# RL7005_IP_SVD register map
Vendor: Realtek
Registers are 32-bit, read-write, reset 0x0 unless marked. A register's access mark holds for its fields unless they carry their own. Offsets are from the block's base; [hi:lo] are bit positions; lines under a group give offsets from that group; {n}, {i} and the like mark numbered series.

## PAGE17
Base 0x40000000
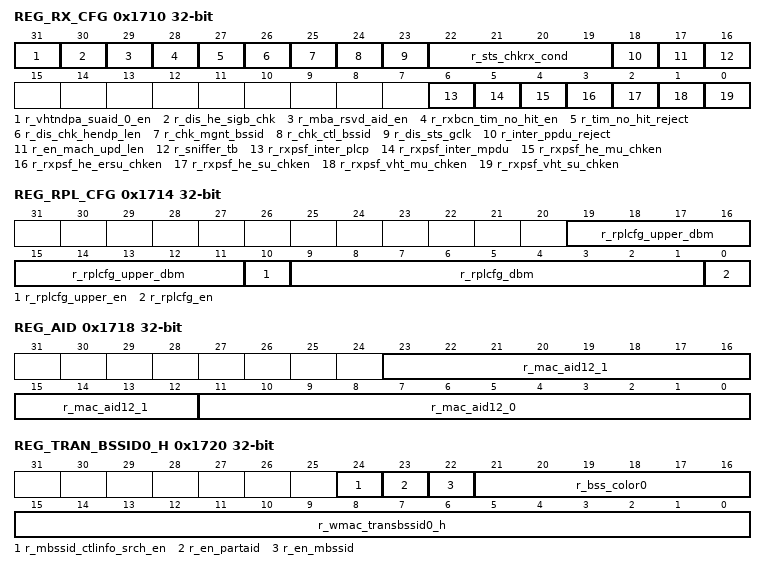
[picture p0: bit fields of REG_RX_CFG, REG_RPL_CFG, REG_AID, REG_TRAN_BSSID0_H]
0x1710 REG_RX_CFG — rx configure register
  [31] r_vhtndpa_suaid_0_en — when set, will receive vht/he su ndpa which aid field is set to 0.
  [30] r_dis_he_sigb_chk — when set, disable check he-mu sigb crc8
  [29] r_mba_rsvd_aid_en — enable parsing resevd aid msta-ba for pre-association
  [28] r_rxbcn_tim_no_hit_en — enable rxbcn_ok_int when receiving bcn with tim_no_hit,set 0: rxbcn_ok_int will only assert when tim_hit
  [27] r_tim_no_hit_reject — enable reject tim no hit beacon
  [26] r_dis_chk_hendp_len — disable check HE NDP lsig length value
  [25] r_chk_mgnt_bssid — enable check management frame bssid
  [24] r_chk_ctl_bssid — enable check trigger,vht/hendpa and block ack bssid
  [23] r_dis_sts_gclk — disable ppdu status clock gating
  [22:19] r_sts_chkrx_cond — check macrx condition when receiving ppdu status
  [18] r_inter_ppdu_reject — enable reject inter ppdu
  [17] r_en_mach_upd_len — enable macrx_pktfifo_ctl update mpdu length in MACHDR_CHK state
  [16] r_sniffer_tb — enable to receive TB PPDU for debug mode
  [6] r_rxpsf_inter_plcp — enable invalid packet check for inter ppdu, inter ppdu valid when plcp is inter bss
  [5] r_rxpsf_inter_mpdu — enable invalid packet check for inter ppdu, inter ppdu valid when plcp and mac header are inter bss
  [4] r_rxpsf_he_mu_chken — enable HE MU invalid packet check for mac header
  [3] r_rxpsf_he_ersu_chken — enable HE ER SU invalid packet check for mac header
  [2] r_rxpsf_he_su_chken — enable HE SU invalid packet check for mac header
  [1] r_rxpsf_vht_mu_chken — enable VHT MU invalid packet check for mac header
  [0] r_rxpsf_vht_su_chken — enable VHT SU invalid packet check for mac header
0x1714 REG_RPL_CFG — rx receive power level configure register
  [19:11] r_rplcfg_upper_dbm — rx power upper level
  [10] r_rplcfg_upper_en — enable use r_rplcfg_upper_dbm as rx power level
  [9:1] r_rplcfg_dbm — rx power level
  [0] r_rplcfg_en — enable use r_rplcfg_dbm as rx power level
0x1718 REG_AID — aid register
  [23:12] r_mac_aid12_1 — aid1
  [11:0] r_mac_aid12_0 — aid0
0x171C REG_TRAN_BSSID0_L — trasmitted bssid register0_l
  [31:0] r_wmac_transbssid0_l — lower 32 bits of transmitted bssid0
0x1720 REG_TRAN_BSSID0_H — trasmitted bssid register0_h
  [24] r_mbssid_ctlinfo_srch_en — when set, rx trigger and vht/he ndpa, will search control info using assocaiated bssid
  [23] r_en_partaid — enable inter ppdu decision according to partial aid for VHT ppdu
  [22] r_en_mbssid — enable multibssid function
  [21:16] r_bss_color0 — bss color of current BSS
  [15:0] r_wmac_transbssid0_h — higher 16 bits of transmitted bssid0
0x1724 REG_TRAN_BSSID1_L — trasmitted bssid register1_l
  [31:0] r_wmac_transbssid1_l — lower 32 bits of transmitted bssid1
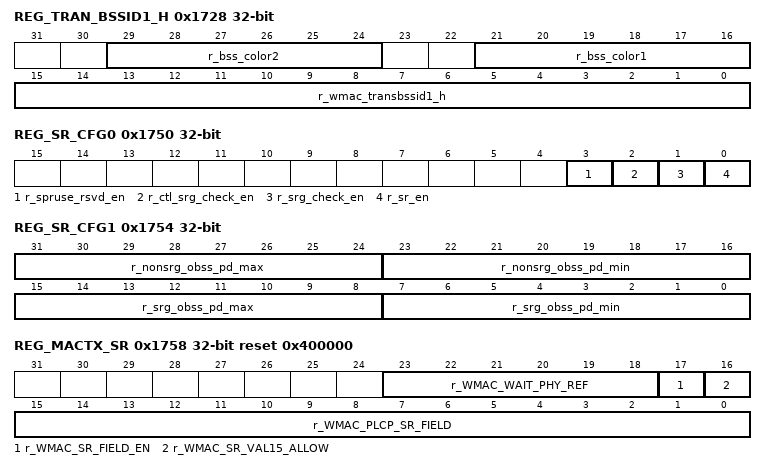
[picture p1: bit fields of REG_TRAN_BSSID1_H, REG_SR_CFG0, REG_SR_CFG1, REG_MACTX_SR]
0x1728 REG_TRAN_BSSID1_H — trasmitted bssid register1_h
  [29:24] r_bss_color2 — bss color of port2
  [21:16] r_bss_color1 — bss color of current BSS
  [15:0] r_wmac_transbssid1_h — higher 16 bits of transmitted bssid1
0x172C REG_GID_POS_EN_l — VHT group id position enable register
  [31:0] r_gid_position_en_l — VHT group id position enable
{0x1730+4i} REG_GID_POS{i} (i=0..3) — VHT group id position{i} register
  [31:0] r_gid_position{i} — VHT group id position{i}
0x1740 REG_BSSCOLOR_BITMAP_L — bss color bitmap register_l
  [31:0] r_bsscolor_bitmap_l — low 32bits bss color bitmap
0x1744 REG_BSSCOLOR_BITMAP_H — bss color bitmap register_h
  [31:0] r_bsscolor_bitmap_h — high 32bits bss color bitmap
0x1748 REG_PBSSID_BITMAP_L — partial bssid bitmap register_l
  [31:0] r_partial_bssid_bitmap_l — low 32bits partial bssid bitmap
0x174C REG_PBSSID_BITMAP_H — partial bssid bitmap register_h
  [31:0] r_partial_bssid_bitmap_h — high 32bits partial bssid bitmap
0x1750 REG_SR_CFG0 — spatial reuse configure register0
  [3] r_spruse_rsvd_en — enable spatial reuse when plcp header spatial reuse field value smaller than 14 or value is 15 and is srg ppdu
  [2] r_ctl_srg_check_en — enable control packet srg ppdu check
  [1] r_srg_check_en — enable srg ppdu check
  [0] r_sr_en — enable spatial reuse function
0x1754 REG_SR_CFG1 — spatial reuse configure register1
  [31:24] r_nonsrg_obss_pd_max — the maximum value of non_SRG OBSS_PD
  [23:16] r_nonsrg_obss_pd_min — the minimum value of non_SRG OBSS_PD
  [15:8] r_srg_obss_pd_max — the maximum value of OBSS_PD
  [7:0] r_srg_obss_pd_min — the minimum value of OBSS_PD
0x1758 REG_MACTX_SR reset 0x400000 — SR field configure
  [23:18] r_WMAC_WAIT_PHY_REF — mactx hang handle, reset mactx if the phy_txen is set and wait the begin pulse of phy_txon timeout
  [17] r_WMAC_SR_FIELD_EN — enable sr field reg cfg
  [16] r_WMAC_SR_VAL15_ALLOW — sr field can be the value 15
  [15:0] r_WMAC_PLCP_SR_FIELD — value of SR field
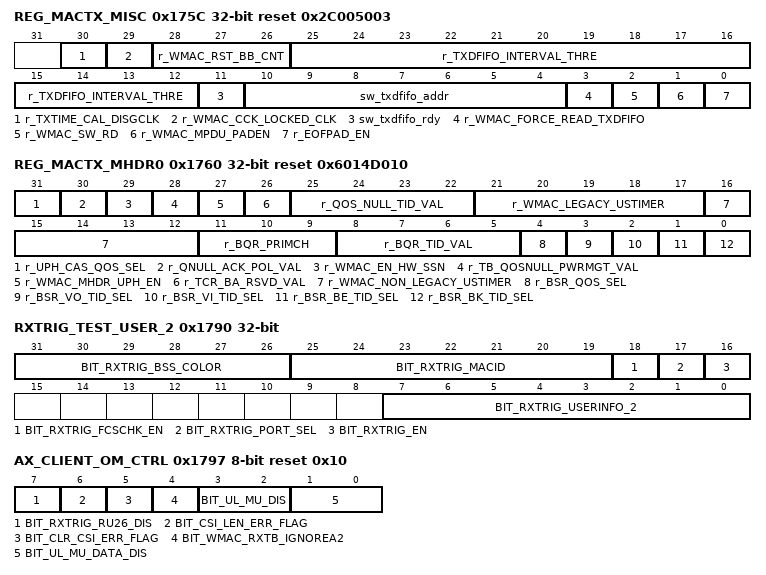
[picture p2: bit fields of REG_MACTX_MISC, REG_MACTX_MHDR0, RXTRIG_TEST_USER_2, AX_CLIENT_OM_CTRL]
0x175C REG_MACTX_MISC reset 0x2C005003 — misc ctrl cfg
  [30] r_TXTIME_CAL_DISGCLK — disable the clk gating for txtime compute module
  [29] r_WMAC_CCK_LOCKED_CLK — indicate that the transmit frequency and symbol clocks are derived from the same oscillator
  [28:26] r_WMAC_RST_BB_CNT — macclk cycle number of wmac_rst_bb signal
  [25:12] r_TXDFIFO_INTERVAL_THRE — the interval threshold between txdfifo write and read pointer, if the interval is smaller than the threshold, mactx_mpdu moudle can pad dummy between mpdu(if eanbled)
  [11] sw_txdfifo_rdy — sw read txd fifo ready
  [10:4] sw_txdfifo_addr — sw read txd fifo address,[6:1] is address, [0] : 0 read low 32bit; 1 read high 32bit;
  [3] r_WMAC_FORCE_READ_TXDFIFO — during tx procedure, force read txd fifo, which is only use at the situation when bb is hang.
  [2] r_WMAC_SW_RD — eanble sw read txdfifo
  [1] r_WMAC_MPDU_PADEN — when txdfifo underflow ,eanble the mactx_mpdu moudle to pad dummy between mpdu.
  [0] r_EOFPAD_EN — enable eof pad operation at the end of mpdu
0x1760 REG_MACTX_MHDR0 reset 0x6014D010 — MAC header configure
  [31] r_UPH_CAS_QOS_SEL — UPH and CAS HTC control field enable
  [30] r_QNULL_ACK_POL_VAL — basic trigger resp tb QOS NULL ack policy bit 0 value
  [29] r_WMAC_EN_HW_SSN — enable the hw ssn for qos null frame.
  [28] r_TB_QOSNULL_PWRMGT_VAL — the power management bit value in tb qos null, used during twt operation
  [27] r_WMAC_MHDR_UPH_EN — eanble reg wirte HTC field of tb_ppdu, which contain UPH a-control(4)
  [26] r_TCR_BA_RSVD_VAL — multi-sta BA bactl rsvd filed value
  [25:22] r_QOS_NULL_TID_VAL — tid value of qos null
  [21:17] r_WMAC_LEGACY_USTIMER — timer cnt before bb fetch txd for ofdm
  [16:12] r_WMAC_NON_LEGACY_USTIMER — timer cnt before bb fetch txd for he/vht/ht/cck
  [11:9] r_BQR_PRIMCH — shift bqr bitmap to the allocatied primary 20M channel
  [8:5] r_BQR_TID_VAL — bandwidth query report TID value
  [4] r_BSR_QOS_SEL — Buffer status report enable
  [3] r_BSR_VO_TID_SEL — 1: tid 7; 0: tid 6;
  [2] r_BSR_VI_TID_SEL — 1: tid 5; 0: tid 4;
  [1] r_BSR_BE_TID_SEL — 1: tid 2; 0: tid 1;
  [0] r_BSR_BK_TID_SEL — 1: tid 3; 0: tid 0;
0x1764 REG_MACTX_MHDR1 — MAC header HTC
  [31:0] r_WMAC_NHDR_HTC — HTC field of tb_ppdu, which contain UPH a-control(4)
0x1768 REG_MACTX_TXD_FIFO ro — fifo do
  [31:0] sw_txdfifo_dout — sw read rxd_out
0x1780 RXTRIG_TEST_COMM_0
  [31:0] BIT_RXTRIG_COMMON_0 — low 32bit of comm field in trigger frame of test mode
0x1784 RXTRIG_TEST_COMM_1
  [31:0] BIT_RXTRIG_COMMON_1 — high32bit of comm field in trigger frame of test mode
0x1788 RXTRIG_TEST_USER_0
  [31:0] BIT_RXTRIG_USERINFO_0 — low 32bit of user field in trigger frame of test mode
0x178C RXTRIG_TEST_USER_1
  [31:0] BIT_RXTRIG_USERINFO_1 — high 32bit of user field in trigger frame of test mode
0x1790 RXTRIG_TEST_USER_2 access per field
  [31:26] BIT_RXTRIG_BSS_COLOR rw — bss color
  [25:19] BIT_RXTRIG_MACID rw — macid
  [18] BIT_RXTRIG_FCSCHK_EN rw — 1:enable fcs check
  [17] BIT_RXTRIG_PORT_SEL rw — port sel
  [16] BIT_RXTRIG_EN wo — enable rx trigger test mode
  [7:0] BIT_RXTRIG_USERINFO_2 rw — msb 8bit of user field in trigger frame of test mode
0x1794 RXTRIG_TEST_CTRL1 8-bit ro
  [7:0] BIT_RXTRIG_STATUS — [7:4]:trig_cntr [3:0]:ctl_state
0x1795 RXTRIG_TEST_CTRL2 16-bit
  [15:0] BIT_RXTRIG_DURATION — duration of trigger frame
0x1797 AX_CLIENT_OM_CTRL 8-bit access per field reset 0x10
  [7] BIT_RXTRIG_RU26_DIS rw — disable response to trigger frame when ru_allocation addressed to me is 26-tone ru
  [6] BIT_CSI_LEN_ERR_FLAG ro — csi_length error flag
  [5] BIT_CLR_CSI_ERR_FLAG rw — clear csi_length error flag
  [4] BIT_WMAC_RXTB_IGNOREA2 rw — will not check a2 when receive tb ppdu
  [3:2] BIT_UL_MU_DIS rw — Disable to respond UL response triggered by any trigger frame. Per port config.
  [1:0] BIT_UL_MU_DATA_DIS rw — Disable to respond UL data triggered by basic trigger frame. Per port config. (BA/ACK/BSR/BQR are still allowed to Tx)
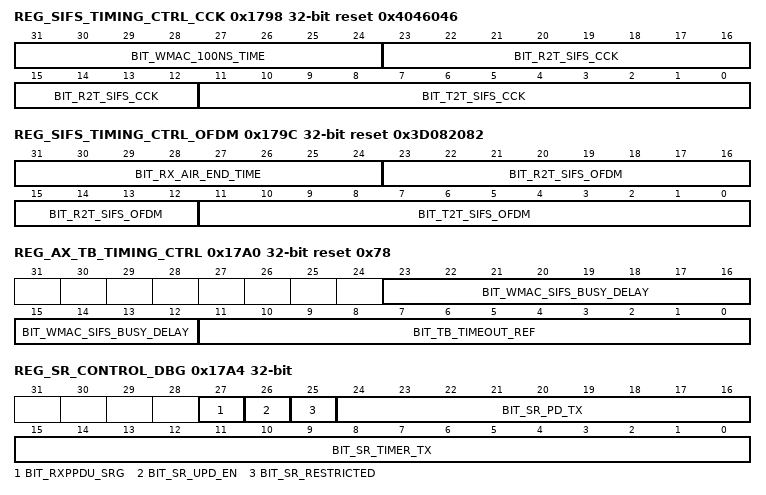
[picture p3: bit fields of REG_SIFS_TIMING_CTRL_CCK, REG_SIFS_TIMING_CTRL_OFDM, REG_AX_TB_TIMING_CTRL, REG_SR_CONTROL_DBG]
0x1798 REG_SIFS_TIMING_CTRL_CCK reset 0x4046046
  [31:24] BIT_WMAC_100NS_TIME — Sets the 100ns time unit used by MAC clock.(DEFAULT:40M CLK,eg:20M clk should set this value to 2)
  [23:12] BIT_R2T_SIFS_CCK — This register sets the SIFS time required for any immediate response for example Data-Ack. It is in unit of 100ns.(default:7us)
  [11:0] BIT_T2T_SIFS_CCK — This register sets the SIFS time required for consecutive TX events for example CTS-Data, or broadcast bursting. It is in unit of 100ns.(default:7us)
0x179C REG_SIFS_TIMING_CTRL_OFDM reset 0x3D082082
  [31:24] BIT_RX_AIR_END_TIME — This register sets the time from cca fall to 6us. It is in unit of 100ns.(default:6.1us)
  [23:12] BIT_R2T_SIFS_OFDM — This register sets the SIFS time required for any immediate response for example Data-Ack. It is in unit of 100ns.(default:13us)
  [11:0] BIT_T2T_SIFS_OFDM — This register sets the SIFS time required for consecutive TX events for example CTS-Data, or broadcast bursting. It is in unit of 100ns.(default:13us)
0x17A0 REG_AX_TB_TIMING_CTRL reset 0x78
  [23:12] BIT_WMAC_SIFS_BUSY_DELAY — This register sets the sifs_busy delay timer, when CCA fall need delay to check edcca or edcca_per20_bitmap It is in unit of 100ns.(default:0us)
  [11:0] BIT_TB_TIMEOUT_REF — This register sets the max time for tb data aggragation, It is in unit of 100ns.(default:12us)
0x17A4 REG_SR_CONTROL_DBG ro
  [27] BIT_RXPPDU_SRG — the received pkt is an srg ppdu
  [26] BIT_SR_UPD_EN — the received pkt is allowed to update basic nav
  [25] BIT_SR_RESTRICTED — the spatial reuse type is restricted
  [24:16] BIT_SR_PD_TX — the value of received power level minus obss_pd_min
  [15:0] BIT_SR_TIMER_TX — time can be used for spatial reuse
0x17A8 REG_SR_CONTROL_DBG1 8-bit reset 0x4
  [7:0] BIT_SR_USABLE_TIMER_THRES — If received pkt can operate spatial reuse,the min threshold for sr_timer_tx. unit:256us(default:1024us)
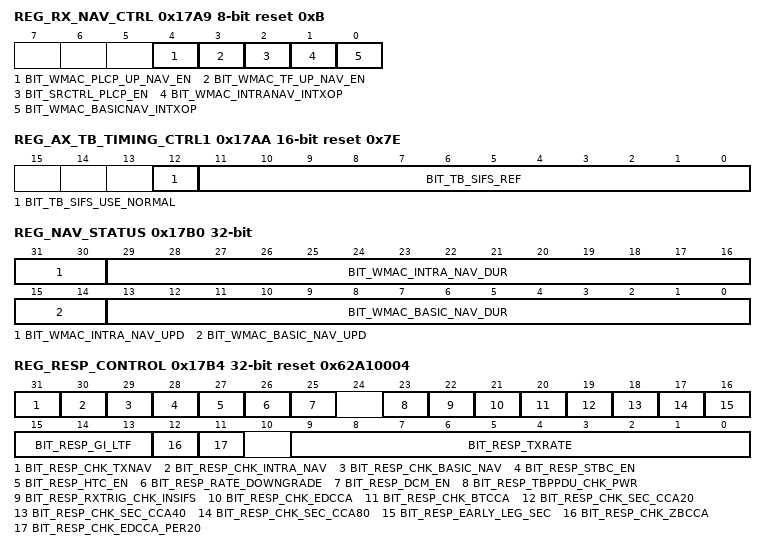
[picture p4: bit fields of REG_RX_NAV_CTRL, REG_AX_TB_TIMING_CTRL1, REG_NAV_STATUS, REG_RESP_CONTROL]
0x17A9 REG_RX_NAV_CTRL 8-bit reset 0xB
  [4] BIT_WMAC_PLCP_UP_NAV_EN — 1:enable using txop_dur in plcp header to update nav
  [3] BIT_WMAC_TF_UP_NAV_EN — 1:enable updating intra nav when receiving trigger frame
  [2] BIT_SRCTRL_PLCP_EN — 1:use txop_dur as sr_tx_timer
  [1] BIT_WMAC_INTRANAV_INTXOP — enable updating intra nav in my txop
  [0] BIT_WMAC_BASICNAV_INTXOP — enable updating basic nav in my txop
0x17AA REG_AX_TB_TIMING_CTRL1 16-bit reset 0x7E
  [12] BIT_TB_SIFS_USE_NORMAL — 1:choose 0x179c sifs when rx trigger 0:choose 0x17A0[11:0] sifs when rx trigger
  [11:0] BIT_TB_SIFS_REF — This register sets the SIFS time required for tb response when receiving trigger frame. It is in unit of 100ns.(default:12.6us)
0x17B0 REG_NAV_STATUS ro
  [31:30] BIT_WMAC_INTRA_NAV_UPD — intra nav updated by 10: plcp header 01: mac header
  [29:16] BIT_WMAC_INTRA_NAV_DUR — intra_nav
  [15:14] BIT_WMAC_BASIC_NAV_UPD — inter nav updated by 10: plcp header 01: mac header
  [13:0] BIT_WMAC_BASIC_NAV_DUR — basic_nav
0x17B4 REG_RESP_CONTROL reset 0x62A10004
  [31] BIT_RESP_CHK_TXNAV — check txnav when need to response
  [30] BIT_RESP_CHK_INTRA_NAV — check intra nav when need to response
  [29] BIT_RESP_CHK_BASIC_NAV — check basic nav when need to response
  [28] BIT_RESP_STBC_EN — enable stbc when need to response
  [27] BIT_RESP_HTC_EN — enable appending htc when need to response
  [26] BIT_RESP_RATE_DOWNGRADE — enable downgrade response rate from HE to VHT, VHT to HT, HE to HT when need to response
  [25] BIT_RESP_DCM_EN — enable using dcm need to response
  [23] BIT_RESP_TBPPDU_CHK_PWR — check tb ppdu tx power when rx trigger, if txpwr_ctrl send signal of abort,will not reply with tb ppdu
  [22] BIT_RESP_RXTRIG_CHK_INSIFS — check whether channel is idle during sifs, if csreq=1 in trigger frame, will not reply with tb ppdu
  [21] BIT_RESP_CHK_EDCCA — check edcca when response
  [20] BIT_RESP_CHK_BTCCA — check btcca when response
  [19] BIT_RESP_CHK_SEC_CCA20 — check sec 20 cca when response
  [18] BIT_RESP_CHK_SEC_CCA40 — check sec 40 cca when response
  [17] BIT_RESP_CHK_SEC_CCA80 — check sec 80 cca when response
  [16] BIT_RESP_EARLY_LEG_SEC — when receive pkt of tkip or wep, While phyrxon down, mac_rxactive on. Ignore mac rx busy or physts_on, respond immediately.
  [15:13] BIT_RESP_GI_LTF — 5:1x+0.8 4:1x+1.6 3:2x+0.8 2:2x+1.6 1:4x+0.8 0:4x+3.2 not support 1x+1.6 when response
  [12] BIT_RESP_CHK_ZBCCA — check zigbee cca when response
  [11] BIT_RESP_CHK_EDCCA_PER20 — check edcca_per20_bitmap_sifs[0] when response
  [9:0] BIT_RESP_TXRATE — tx rate use to decide response rate
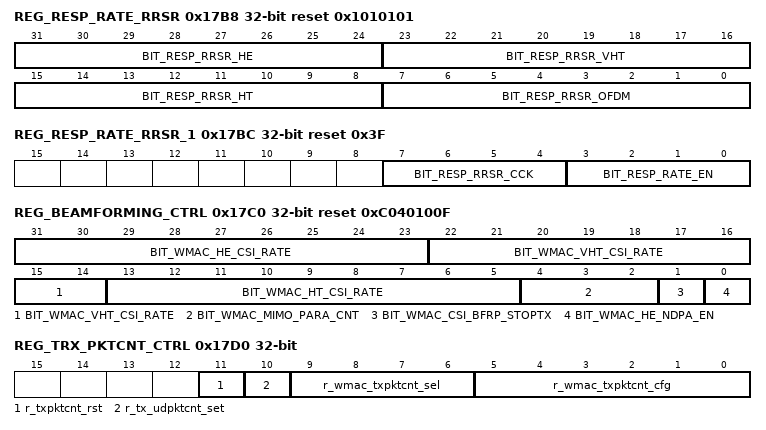
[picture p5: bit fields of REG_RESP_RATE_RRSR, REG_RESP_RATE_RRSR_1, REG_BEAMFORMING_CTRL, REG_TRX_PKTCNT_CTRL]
0x17B8 REG_RESP_RATE_RRSR reset 0x1010101
  [31:24] BIT_RESP_RRSR_HE — Data Rate Control Table Register BitMap to indicate the response/protection/expected_response rate to use in this BSS. All management and control response frames should obey the rates set in the bitmap. Each bit is mapped as the following: HE 1SS MCS0~MCS7 Response rate must be less than or equal to the rate of the initiating frame. If none of the bits are set, no response is generated by Rtl8712. If both the legacy rates and HT rates are defined as Basic Rates, fill in only the legacy portion of the bitmap. If only HT rates are defined as Basic Rates, fill in both the legacy and HT portion of the bitmap.
  [23:16] BIT_RESP_RRSR_VHT — VHT 1SS MCS0~MCS7
  [15:8] BIT_RESP_RRSR_HT — HT 1SS MCS0~MCS7
  [7:0] BIT_RESP_RRSR_OFDM — {6M, 9M, 12M, 18M, 24M, 36M, 48M, 54M}
0x17BC REG_RESP_RATE_RRSR_1 reset 0x3F
  [7:4] BIT_RESP_RRSR_CCK — {1M, 2M, 5.5M, 11M }
  [3:0] BIT_RESP_RATE_EN — [0]:enable respnse rate of CCK and OFDM [1]:enable respnse rate of HT [2]:enable respnse rate of VHT [3]:enable respnse rate of HE
0x17C0 REG_BEAMFORMING_CTRL reset 0xC040100F
  [31:23] BIT_WMAC_HE_CSI_RATE — HE CSI init rate(HE mode+NSS + MCS)
  [22:14] BIT_WMAC_VHT_CSI_RATE — VHT CSI init rate(VHT mode+ NSS + MCS)
  [13:5] BIT_WMAC_HT_CSI_RATE — HT CSI init rate(HT mode + NSS + MCS)
  [4:2] BIT_WMAC_MIMO_PARA_CNT — width of mimo_para_en,deafult:3(mac clk:40M,pluse width:100ns)
  [1] BIT_WMAC_CSI_BFRP_STOPTX — stop tx when rx ndpa/ndp and wait for bfrp poll frame
  [0] BIT_WMAC_HE_NDPA_EN — Set to 1, MAC would inform BB of preparing to receive NDP if the received NDPA is valid.
0x17C4 REG_CSI_RRSR_BITMAP reset 0x3
  [31:0] BIT_WMAC_CSI_RRSR_BITMAP — BitMap to indicate the CSI frame rate in this BSS. Each bit is mapped as the following: Bit[7:0] = OFDM {6M, 9M, 12M, 18M, 24M, 36M, 48M, 54M} Bit[15:8] = HT MCS0~MCS7 BIT[23:16] = VHT 1SS MCS0~7 bit[31:24] = HE 1SS MCS0~7 The modulation of response rate must be less than or equal to the rate of the initiating frame. If none of the bits are set, no response is generated by Rtl8712. If both legacy rates and HT rates are defined as Basic Rates, fill in only the legacy portion of the bitmap. If only HT rates are defined as Basic Rates, fill in both the legacy and HT portion of the bitmap.
0x17C8 REG_LBK_CFG reset 0x12
  [11:0] r_maclbk_rdy_period — tdrdy/rdrdy interval count
0x17CC REG_GID_POS_EN_H — VHT group id position enable register
  [31:0] r_gid_position_en_h — VHT group id position enable
0x17D0 REG_TRX_PKTCNT_CTRL
  [11] r_txpktcnt_rst — Reset tx packet counter, write "one" to set the counter to zero
  [10] r_tx_udpktcnt_set — Set user define packet configure, write one setting, it is only valid for r_wmac_txpktcnt_sel (4'd0 ~ 4'd3)
  [9:6] r_wmac_txpktcnt_sel — Tx packet counter report selection 4'd0: user define 0 counter 4'd1: user define 1 counter 4'd2: user define 2 counter 4'd3: user define 3 counter 4'd4: HT mpdu tx ok counter 4'd5: VHT SU mpdu tx ok counter 4'd6: HE SU mpdu tx ok counter 4'd7: HE TB mpdu tx ok counter 4'd8: CCK ppdu tx ok counter 4'd9: OFDM ppdu tx ok counter 4'd10: HT ppdu tx ok counter 4'd11: VHT SU ppdu tx ok counter 4'd12: HE SU ppdu tx ok counter 4'd13: HE TB ppdu tx ok counter 4'd14~4'd15: RSVD
  [5:0] r_wmac_txpktcnt_cfg — Tx packet conuter user define configuration [5:2]:subtype [1:0]:type
0x17D4 REG_TRX_PKTCNT_RPT ro
  [25:0] ro_wmac_txpktcnt_rpt — [25:22]:Tx packet counter report selection,r_wmac_txpktcnt_sel [21:16]:user define->tx packet type,[21:18]:subtype,[17:16]:type; others->6'h0 [15:0]:The tx reported counter value corresponding to Report type selected
0x17D8 REG_BEAMFORMING_MIMO_STATUS ro
  [23:0] ro_wmac_he_csi_mimo_h — msb 24bit of he csi mimo field
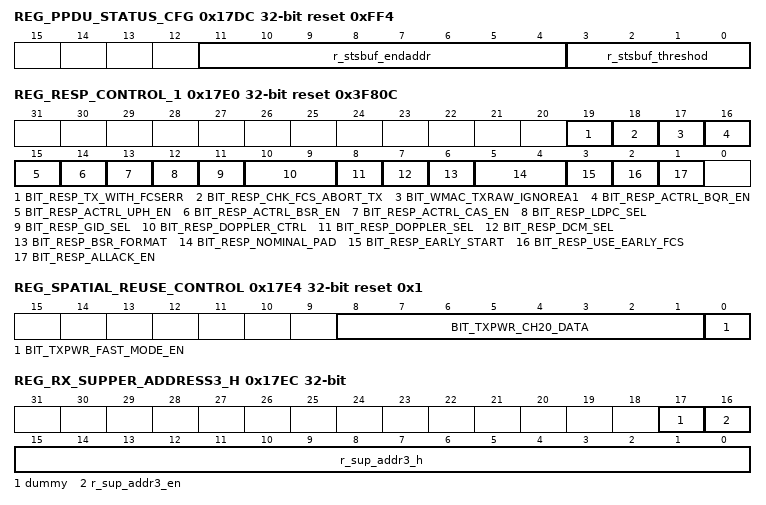
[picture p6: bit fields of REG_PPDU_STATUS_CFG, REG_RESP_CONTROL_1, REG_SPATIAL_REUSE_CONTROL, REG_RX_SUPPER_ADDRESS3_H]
0x17DC REG_PPDU_STATUS_CFG reset 0xFF4
  [11:4] r_stsbuf_endaddr — ppdu status buffer end address
  [3:0] r_stsbuf_threshod — ppdu status buffer almost full threshold
0x17E0 REG_RESP_CONTROL_1 reset 0x3F80C
  [19] BIT_RESP_TX_WITH_FCSERR — 1:if resp_chk_fcs is low and mactx starts to generate mpdu,will tx response with wrong crc32
  [18] BIT_RESP_CHK_FCS_ABORT_TX — If set to 1, will not response ack if fcs is not rdy when sifs reach if set to 0, will response ack if fcs is not rdy when sifs reach
  [17] BIT_WMAC_TXRAW_IGNOREA1 — If set to 1, will not check A1 of rxpkt when txraw
  [16] BIT_RESP_ACTRL_BQR_EN — If set to 1, HW would update BQR info to A-CTRL
  [15] BIT_RESP_ACTRL_UPH_EN — If set to 1, HW would update UPH info to A-CTRL
  [14] BIT_RESP_ACTRL_BSR_EN — If set to 1, HW would update BSR info to A-CTRL
  [13] BIT_RESP_ACTRL_CAS_EN — If set to 1, HW would update CAS info to A-CTRL
  [12] BIT_RESP_LDPC_SEL — 1: follow ctrl reg(0x668[15]) 0: follow rxpkt
  [11] BIT_RESP_GID_SEL — HE SIG-A content 1 : group id=0, 0 : group id=63
  [10:9] BIT_RESP_DOPPLER_CTRL — 0: Doppler unsupported 1: Doppler supported without moving 2: 10 symbol midamble periodicity 3: 20 symbol midamble periodicity
  [8] BIT_RESP_DOPPLER_SEL — 1: follow ctrl reg(0x17E0[10]) 0: follow rxpkt
  [7] BIT_RESP_DCM_SEL — 1: follow ctrl reg(0x17b4[25]) 0: follow rxpkt
  [6] BIT_RESP_BSR_FORMAT — 0: legacy format of queue size 1: HE
  [5:4] BIT_RESP_NOMINAL_PAD — nominal pkt pad info when response
  [3] BIT_RESP_EARLY_START — when set to 1:use mac header rdy when rx data frame and use aid fit when rx trigger frame, and use fcsok otherwise to start responding process when set to 0:use fcs ok to start responding process when rx any frame need reply
  [2] BIT_RESP_USE_EARLY_FCS — use fcs result from rxpktfifo instead of macrx_parser when receive packet used wep/tkip
  [1] BIT_RESP_ALLACK_EN — enable response with all-ack MBA
0x17E4 REG_SPATIAL_REUSE_CONTROL reset 0x1
  [8:1] BIT_TXPWR_CH20_DATA — indicate which 20M channel is punctured in RU
  [0] BIT_TXPWR_FAST_MODE_EN — fast mode enable for txpwr_ctrl,tie 1 for AMEBAD2
0x17E8 REG_RX_SUPPER_ADDRESS3_L
  [31:0] r_sup_addr3_l — Address3 for data packet check. When address3 is match, RX will receive the packet to RXFF without considering other filter condition except crc32
0x17EC REG_RX_SUPPER_ADDRESS3_H
  [17] dummy
  [16] r_sup_addr3_en — when set, enable check supper Address3
  [15:0] r_sup_addr3_h — Address3 for data packet check. When address3 is match, RX will receive the mpdu to RXFF without considering other filter condition except crc32
0x17F0 REG_MASK_LA_TRX_DBG_L
  [31:0] BIT_LA_TRX_PATTERN_MASK_L — used for mask one or more bits of debug port
0x17F4 REG_MASK_LA_TRX_DBG_H
  [31:0] BIT_LA_TRX_PATTERN_MASK_H — used for mask one or more bits of debug port
0x17F8 REG_REF_LA_TRX_DBG_L
  [31:0] BIT_LA_TRX_PATTERN_REF_L — used for mask one or more bits of debug port
0x17FC REG_REF_LA_TRX_DBG_H
  [31:0] BIT_LA_TRX_PATTERN_REF_H — used for mask one or more bits of debug port
